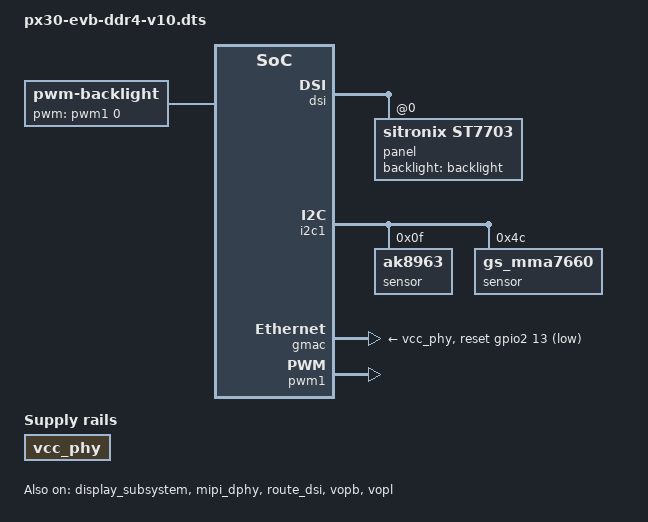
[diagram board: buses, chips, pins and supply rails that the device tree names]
/*
 * Copyright (c) 2017 Fuzhou Rockchip Electronics Co., Ltd
 *
 * SPDX-License-Identifier: (GPL-2.0+ OR MIT)
 */

/dts-v1/;
#include <dt-bindings/display/drm_mipi_dsi.h>
#include <dt-bindings/sensor-dev.h>
#include "px30.dtsi"
#include "px30-android.dtsi"

/ {
	backlight: backlight {
		compatible = "pwm-backlight";
		pwms = <&pwm1 0 25000 0>;
		brightness-levels = <
			  0   1   2   3   4   5   6   7
			  8   9  10  11  12  13  14  15
			 16  17  18  19  20  21  22  23
			 24  25  26  27  28  29  30  31
			 32  33  34  35  36  37  38  39
			 40  41  42  43  44  45  46  47
			 48  49  50  51  52  53  54  55
			 56  57  58  59  60  61  62  63
			 64  65  66  67  68  69  70  71
			 72  73  74  75  76  77  78  79
			 80  81  82  83  84  85  86  87
			 88  89  90  91  92  93  94  95
			 96  97  98  99 100 101 102 103
			104 105 106 107 108 109 110 111
			112 113 114 115 116 117 118 119
			120 121 122 123 124 125 126 127
			128 129 130 131 132 133 134 135
			136 137 138 139 140 141 142 143
			144 145 146 147 148 149 150 151
			152 153 154 155 156 157 158 159
			160 161 162 163 164 165 166 167
			168 169 170 171 172 173 174 175
			176 177 178 179 180 181 182 183
			184 185 186 187 188 189 190 191
			192 193 194 195 196 197 198 199
			200 201 202 203 204 205 206 207
			208 209 210 211 212 213 214 215
			216 217 218 219 220 221 222 223
			224 225 226 227 228 229 230 231
			232 233 234 235 236 237 238 239
			240 241 242 243 244 245 246 247
			248 249 250 251 252 253 254 255>;
		default-brightness-level = <200>;
	};

	vcc_phy: vcc-phy-regulator {
		compatible = "regulator-fixed";
		regulator-name = "vcc_phy";
		regulator-always-on;
		regulator-boot-on;
	};
};

&display_subsystem {
	status = "okay";
};

&dsi {
	status = "okay";

	panel@0 {
		compatible = "sitronix,st7703", "simple-panel-dsi";
		reg = <0>;
		//power-supply = <&vcc3v3_lcd>;
		backlight = <&backlight>;
		prepare-delay-ms = <2>;
		reset-delay-ms = <1>;
		init-delay-ms = <20>;
		enable-delay-ms = <120>;
		disable-delay-ms = <50>;
		unprepare-delay-ms = <20>;

		width-mm = <68>;
		height-mm = <121>;

		dsi,flags = <(MIPI_DSI_MODE_VIDEO | MIPI_DSI_MODE_VIDEO_BURST |
			      MIPI_DSI_MODE_LPM | MIPI_DSI_MODE_EOT_PACKET)>;
		dsi,format = <MIPI_DSI_FMT_RGB888>;
		dsi,lanes = <4>;

		panel-init-sequence = [
			05 fa 01 11
			39 00 04 b9 f1 12 83
			39 00 1c ba 33 81 05 f9 0e 0e 00 00 00
				 00 00 00 00 00 44 25 00 91 0a
				 00 00 02 4f 01 00 00 37
			15 00 02 b8 25
			39 00 04 bf 02 11 00
			39 00 0b b3 0c 10 0a 50 03 ff 00 00 00
				 00
			39 00 0a c0 73 73 50 50 00 00 08 70 00
			15 00 02 bc 46
			15 00 02 cc 0b
			15 00 02 b4 80
			39 00 04 b2 c8 12 30
			39 00 0f e3 07 07 0b 0b 03 0b 00 00 00
				 00 ff 00 c0 10
			39 00 0d c1 53 00 1e 1e 77 e1 cc dd 67
				 77 33 33
			39 00 07 c6 00 00 ff ff 01 ff
			39 00 03 b5 09 09
			39 00 03 b6 87 95
			39 00 40 e9 c2 10 05 05 10 05 a0 12 31
				 23 3f 81 0a a0 37 18 00 80 01
				 00 00 00 00 80 01 00 00 00 48
				 f8 86 42 08 88 88 80 88 88 88
				 58 f8 87 53 18 88 88 81 88 88
				 88 00 00 00 01 00 00 00 00 00
				 00 00 00 00
			39 00 3e ea 00 1a 00 00 00 00 02 00 00
				 00 00 00 1f 88 81 35 78 88 88
				 85 88 88 88 0f 88 80 24 68 88
				 88 84 88 88 88 23 10 00 00 1c
				 00 00 00 00 00 00 00 00 00 00
				 00 00 00 00 00 30 05 a0 00 00
				 00 00
			39 00 23 e0 00 06 08 2a 31 3f 38 36 07
				 0c 0d 11 13 12 13 11 18 00 06
				 08 2a 31 3f 38 36 07 0c 0d 11
				 13 12 13 11 18
			05 32 01 29
		];

		panel-exit-sequence = [
			05 00 01 28
			05 00 01 10
		];

		display-timings {
			native-mode = <&timing0>;

			timing0: timing0 {
				clock-frequency = <64000000>;
				hactive = <720>;
				vactive = <1280>;
				hfront-porch = <40>;
				hsync-len = <10>;
				hback-porch = <40>;
				vfront-porch = <22>;
				vsync-len = <4>;
				vback-porch = <11>;
				hsync-active = <0>;
				vsync-active = <0>;
				de-active = <0>;
				pixelclk-active = <0>;
			};
		};
	};
};

&i2c1 {
	status = "okay";

	sensor@0f {
		status = "okay";
		compatible = "ak8963";
		reg = <0x0f>;
		type = <SENSOR_TYPE_COMPASS>;
		irq_enable = <0>;
		poll_delay_ms = <30>;
		layout = <1>;
		reprobe_en = <1>;
	};

	sensor@4c {
		status = "okay";
		compatible = "gs_mma7660";
		reg = <0x4c>;
		type = <SENSOR_TYPE_ACCEL>;
		irq_enable = <0>;
		poll_delay_ms = <30>;
		layout = <6>;
		reprobe_en = <1>;
	};
};

&dsi_in_vopl {
	status = "disabled";
};

&gmac {
	phy-supply = <&vcc_phy>;
	clock_in_out = "output";
	snps,reset-gpio = <&gpio2 13 GPIO_ACTIVE_LOW>;
	snps,reset-active-low;
	snps,reset-delays-us = <0 50000 50000>;
	status = "okay";
};

&mipi_dphy {
	status = "okay";
};

&pwm1 {
	status = "okay";
};

&route_dsi {
	status = "okay";
};

&vopb {
	status = "okay";
};

&vopb_mmu {
	status = "okay";
};

&vopl {
	status = "okay";
};

&vopl_mmu {
	status = "okay";
};
